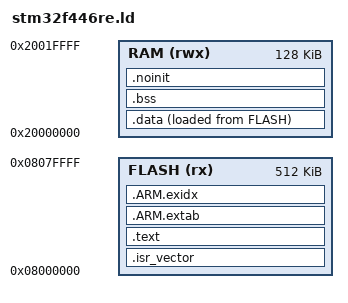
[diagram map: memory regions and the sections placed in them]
ENTRY(Reset_Handler)

MEMORY
{
    FLASH (rx)  : ORIGIN = 0x08000000, LENGTH = 512K
    RAM   (rwx) : ORIGIN = 0x20000000, LENGTH = 128K
}

_estack = ORIGIN(RAM) + LENGTH(RAM);
_stack_limit = _estack - 2K;

SECTIONS
{
    .isr_vector ORIGIN(FLASH) :
    {
        . = ALIGN(4);
        _vector_table = .;
        KEEP(*(.isr_vector))
        _vector_table_end = .;
    } > FLASH

    .text :
    {
        . = ALIGN(4);
        *(.text .text.*)
        *(.rodata .rodata.*)
        *(.glue_7 .glue_7t)
        KEEP(*(.init))
        KEEP(*(.fini))
        . = ALIGN(4);
        _etext = .;
    } > FLASH

    .ARM.extab :
    {
        *(.ARM.extab* .gnu.linkonce.armextab.*)
    } > FLASH

    .ARM.exidx :
    {
        __exidx_start = .;
        *(.ARM.exidx* .gnu.linkonce.armexidx.*)
        __exidx_end = .;
    } > FLASH

    .data :
    {
        . = ALIGN(4);
        _sdata = .;
        *(.data .data.*)
        . = ALIGN(4);
        _edata = .;
    } > RAM AT > FLASH
    _sidata = LOADADDR(.data);

    .bss (NOLOAD) :
    {
        . = ALIGN(4);
        _sbss = .;
        *(.bss .bss.*)
        *(COMMON)
        . = ALIGN(4);
        _ebss = .;
    } > RAM

    .noinit (NOLOAD) :
    {
        . = ALIGN(4);
        *(.noinit .noinit.*)
        . = ALIGN(4);
    } > RAM

    _end = .;

    /DISCARD/ :
    {
        *(.comment)
        *(.note*)
    }
}

ASSERT(_vector_table == ORIGIN(FLASH), "vector table must begin at flash origin")
ASSERT((_vector_table_end - _vector_table) == 0x1C4,
       "STM32F446 vector table must contain 113 entries")
ASSERT((_estack & 7) == 0, "initial MSP must be 8-byte aligned")
ASSERT(_end <= _stack_limit, "static RAM overlaps reserved 2 KiB MSP stack")
